# w600 register map
File version: v0.1
Registers are 32-bit, read-write, reset 0x0 unless marked. A register's access mark holds for its fields unless they carry their own. Offsets are from the block's base; [hi:lo] are bit positions; {n}, {i} and the like mark numbered series; <NAME> marks a mode.

## spi
Base 0x40000200
0x00 ch_cfg — 用以对收发通道的相关项进行一些配置
  [30:23] rx_invalid_bit — 表示接收通路在开始接收时，前多少 bit 是无效数据，这些无效数据需要直接扔掉，不进入Rx FIFO。只有后续的数据进入Rx FIFO本寄存器与Tx/Rx length 配合使用。最后实际存入 Rx FIFO 的数据量为Tx/Rx length- RX_INVALID_BIT注：master 模式有效Motorola/ TI 模式有效
  [18:3] tx — /Rx lengthSpi 在传输时，有效的SCK 数也间接的反映了发送或者接收数据的长度。当（TxChOn=1，RxChOn=1）时，表示发送的 bit 数，以及最大接收的bit 数（具体接收多少与RX_INVALID_BIT 有关）当（TxChOn=1，RxChOn=0）时，表示发送的bit 数，当（TxChOn=0，RxChOn=1）时，表示最大接收的 bit 数（具体接收多少与 RX_INVALID_BIT 有关，实际接收数为Tx/Rx length - RX_INVALID_BIT）当（TxChOn=0，RxChOn=0）时，无意义。注：master 有效Motorola/TI/microwire 模式有效
  [0] rsv
  [0] clear — FIFOs，清除 Tx 和Rx FIFO 的内容,同时同步复位master 和slave 所有电路（配置寄存器除外）软件置 1，硬件清 0注：master/slave 都有效Motorola/TI/microwire 模式有效
    0=不清除FIFO; 1=清除有效
  [0] continue — mode，该模式下，spi 发送不受Tx FIFO 空的影响。，持续传输，直至整个传输过程完成。Rx FIFO 满后，SCK 停止翻转，等待RX FIFO 有空间接收数据满，则需要暂停传输，直至rx fifo 可以存数为止注：master 有效一般情况下，不设置该模式。开启该模式时，如果tx fifo 中没有数据，有可能导致无效数据先发送出去。所以请先填入数据后，再启动spi masterMotorola/TI/microwire 模式有效
    0=normal,Tx FIFO 空后，需要等待FIFO 中出现数据，SCK 停止翻转，同理，; 1=continue mode，Tx fifo 空，仍可以传输，直至传输完成，但此时如果rx fifo
  [0] rxchon — 注：master/slave 都有效Motorola/TI/microwire 模式有效
    0=: Rx channel off; 1=: Rx channel on
  [0] txchon — 注：master/slave 都有效Motorola/TI/microwire 模式有效
    0=: Tx channel off; 1=: Tx channel on
  [0] chip — selects注：master 有效Motorola/TI/microwire 模式有效
    0=SPI_CS 有效信号为 0; 1=SPI_CS 有效信号为 1
  [0] force — CS out该信号配合Chip selects 可以实现输出csn 信号可编程，即该信号为 1 时，spi_cs =Chip selects注：master 有效Motorola/TI/microwire 模式有效
    0=spi_cs 信号输出由硬件控制; 1=spi_cs 信号输出由软件控制，具体输出值为Chip selects
  [0] spi — start,命令 SPI 开始接收或者发送，写 1 为spi 开始工作，之后，自动归零Motorola/TI/microwire 模式有效
    0=停止spi 工作; 1=启动spi 的一次发送或者接收，自动归零注master 有效
0x04 spi_cfg reset 0x4 — 对 SPI 通信相关项进行配置
  [31:19] rsv
  [18:17] fram — FORMAT选择master 支持那个厂家的协议注：master 有效
    0=:motorola 2’b01:TI; 2=:microwire 2’b11:RSV
  [14:12] cs — hold， spi_cs 在数据传输完成后持续有效的时间，即spi_cs 的hold 时间注： master 有效Motorola 模式有效
    0=>=1 个APB 总线 CLK; 1=>=2 个APB 总线CLK; 2=>=4 个APB 总线 CLK; 3=>=8 个APB 总线 CLK; 4=>=16 个APB 总线 CLK; 5=>=32 个APB 总线 CLK; 6=>=64 个APB 总线 CLK; 7=>=127 个APB 总线 CLK
  [11:9] cs — setup， spi_cs 在数据传输前提前有效的时间，即spi_cs 的setup 时间Motorola 模式有效注：master 有效
    0=>=1 个APB 总线 CLK; 1=>=2 个APB 总线 CLK; 2=>=4 个APB 总线 CLK; 3=>=8 个APB 总线 CLK; 4=>=16 个APB 总线 CLK; 5=>=32 个APB 总线 CLK; 6=>=64 个APB 总线 CLK; 7=>=127 个APB 总线 CLK
  [8:7] spi — -out delay, SPI 数据输出相对与SCK 的delay，主要是为了hold time 考虑。[8:7] 系统时钟周期数(APB clock)注：master/slave 都有效Motorola 模式有效
    {v}={v} (v=0..3)
  [6:4] frame — delay，默认在一帧（spi_cs 有效期间）传输结束到下一帧开始的间隔为SCK时钟周期的一半，即SPI_CS 无效时间。但为了兼容性，此处可配置。默认至少0.5SCK [6:4] SCK clock例如，按照 block 模式传输 128byte 的数据，数据传输完成后，会加入所设置的延迟时间。注：master 有效
    0=0; 1=2; 2=4; 3=8; 4=16; 5=32; 6=64; 7=127
  [0] spi_tx — pin always drivenMotorola/TI/microwire 模式有效
    0=spi 输出只有在spi_cs 有效时，被驱动，其它时间为三态; 1=spi 输出一直有驱动，即使没有数据传输注master/slave 都有效
  [0] rsv
  [0] bigendian
    0=数据格式采用小端模式，即传输过程中，先发低字节; 1=数据格式采用大端模式，即传输过程中，先发高字节
  [0] master — /SLAVE注：master/slave 都有效
    0=slave，该设备是slave 1’b1master，该设备是master
  [0] spi — CPHA注：master/slave 都有效Motorola 模式有效
    0=传输模式A; 1=传输模式B
  [0] spi — CPOL，SCK 在 IDLE 时的极性注：master/slave 都有效Motorola 模式有效
    0=SCK IDLE 时为 0; 1=SCK IDLE 时为 1
0x08 clk_cfg — 用以设置时钟分频系数
  [31:16] rsv
  [31:16] rsv
  [15:0] divider — FSCK = FAPB_CLK/ ( 2 x (Divider +1))注：master 有效Motorola/TI/microwire 模式有效
  [15:0] divider — FSCK = FAPB_CLK/ ( 2 x (Divider +1))注：master 有效Motorola/TI/microwire 模式有效
0x0C mode_cfg — 配置传输模式
  [31:9] rsv
  [8:6] rxtrigger — levelRX FIFO 存储的数据触发中断或者DMA 请求的阈值：0~7word只有rxbuffer 中的数据大于RxTrigger level，才会触发中断或者请求DMA 搬移注：master/slave 都有效Motorola/TI/microwire 模式有效
  [4:2] txtrigger — levelTX FIFO 存储的数据触发中断或者DMA 请求的阈值：0~7word只有txbuffer 中的数据大于等于TxTrigger level，才会触发中断或者请求 DMA 搬移注：master/slave 都有效Motorola/TI/microwire 模式有效
  [0] rsv
  [0] rxdma — On，采用DMA 搬移数据使能注：master/slave 都有效Motorola/TI/microwire 模式有效
    0=不采用DMA，; 1=采用DMA
  [0] txdma — On，采用DMA 搬移数据使能注：master/slave 都有效Motorola/TI/microwire 模式有效
    0=不采用DMA，; 1=采用DMA
0x10 spi_int_mask reset 0xFF — 屏蔽或者使能相关中断
  [31:8] rsv
  [0] inten_spi_timeout — Motorola/TI/microwire 模式有效
    0=允许产生spi_timeout 中断 1’b1 不允许产生spi_timeout 中断注master/slave 都有效
  [0] inten_spi_done — 注：master/slave 都有效Motorola/TI/microwire 模式有效
    0=spi 发送或者接收完成，允许产生中断; 1=spi 发送或者接收完成，不允许产生中断
  [0] intenrxoverrun — 注：master/slave 都有效Motorola/TI/microwire 模式有效
    0=Rx FIFO overflow 中断使能; 1=Rx FIFO overflow 中断不使能
  [0] intenrxunderrun — 注：master/slave 都有效Motorola/TI/microwire 模式有效
    0=Rx FIFO underflow 中断不使能; 1=Rx FIFO underflow 中断使能
  [0] intentxoverrun — 注：master/slave 都有效Motorola/TI/microwire 模式有效
    0=Tx FIFO overflow 中断使能; 1=Tx FIFO overflow 中断不使能
  [0] intentxunderrun — 注：master/slave 都有效Motorola/TI/microwire 模式有效
    0=Tx FIFO underflow 中断使能; 1=Tx FIFO underflow 中断不使能
  [0] intenrxfifordy — 注：master/slave 都有效Motorola/TI/microwire 模式有效
    0=Rx FIFO 有数据上传中断使能; 1=Rx FIFO 有数据上传中断不使能
  [0] intentxfifordy — 注：master/slave 都有效Motorola/TI/microwire 模式有效
    0=Tx FIFO 可以向TX FIFO 写数据中断使能; 1=Tx FIFO 可以向TX FIFO 写数据中断不使能
0x14 spi_int_source — 用于查询中断源
  [31:8] rsv
  [0] spi_timeout — 注：master/slave 都有效Motorola/TI/microwire 模式有效
    0=rxfifo 中没有结尾数据需要CPU 取走; 1=rxfifo 中有结尾数据需要CPU 取走写 1 清零
  [0] spi_done — 注：master/slave 都有效Motorola/TI/microwire 模式有效
    0=SPI 发送或者接收没有完成; 1=SPI 发送或者接收完成写 1 清零
  [0] rxoverrun — 写 1 清零注：master/slave 都有效Motorola/TI/microwire 模式有效
    0=Rx FIFO overflow 1’b1Rx FIFO overflow
  [0] rxunderrun — 注：master/slave 都有效Motorola/TI/microwire 模式有效
    0=Rx FIFO underflow 1’b1Rx FIFO underflow写 1 清零
  [0] txoverrun — 注：master/slave 都有效Motorola/TI/microwire 模式有效
    0=Tx FIFO overflow 1’b1Tx FIFO overflow写 1 清零
  [0] txunderrun — 在 continue mode = 1 的情况下，永远不会产生该中断。注：master/slave 都有效Motorola/TI/microwire 模式有效
    0=Tx FIFO underflow 1’b1Tx FIFO underflow写 1 清零
  [0] rxfifordy — 写 1 清零注：master/slave 都有效Motorola/TI/microwire 模式有效
    0=Rx FIFO 数据量<= RxTrigger level，不需要上传 1’b1Rx FIFO 数据量> RxTrigger level，要求上传
  [0] txfifordy — 注：master/slave 都有效Motorola/TI/microwire 模式有效
    0=Tx FIFO 数据量 > TxTrigger level，不可以向TX FIFO 写数据 1’b1Tx FIFO 数据量 <= TxTrigger level，可以向TX FIFO 写数据写 1 清零
0x18 spi_status ro — 列举 SPI 通信中的相关状态
  [31:13] rsv
  [11:6] rx — FIFO fill levelRx FIFO 中数据量，单位为字节注：master/slave 都有效Motorola/TI/microwire 模式有效
  [0] spi — Busy注：master/slave 都有效Motorola/TI/microwire 模式有效
    on read: 0=SPI 没有发送和接收任务; 1=SPI 处于发送或者接收过程
  [5:0] tx — FIFO fill levelTx FIFO 中数据量，单位为字节注：master/slave 都有效Motorola/TI/microwire 模式有效
0x1C spi_time_out — 设置 SPI 通信超时
  [0] spi_timer_en — 注：master/slave 都有效Motorola/TI/microwire 模式有效
    0=不允许timer 计时; 1=:允许timer 计时
  [30:0] spi_time_out — 当一次传输完成后，在接收通路 rxfifo 中，结尾的数据如果不能触发接收中断RxFifoRdy 或者DMA 请求时，需要采用计时机制来通知CPU 搬走结尾数据。具体方法：当 rxfifo 处于idle 状态下（没有读写操作，没有 dma 请求，cs 无效，rxfifo中有数据，且数据量小于等于 RxTrigger level），开始计数，达到本寄存器设置的值，则触发timeout 中断，请求CPU 搬走结尾数据。任何对rxfifo 的读写操作都会清楚timeout 计时器。所表示的时间为： T = SPI_TIME_OUT/FAPB_CLK注：master/slave 都有效Motorola/TI/microwire 模式有效
0x20 spi_tx_data — TX FIFO，用于存放待发送数据
  [31:0] spi_tx_data — 向Tx FIFO 写数据的窗口地址注：master/slave 都有效Motorola/TI/microwire 模式有效
0x24 trans_mode — 设置传输模式
  [31:30] rsv
  [29:24] ti_blk_len — 在TI 的时序模式下，每个 block 传输的长度，即每次 CS 有效之后的传输数据长度。支持 4~32bit……..TI 模式有效
    4=: 4bit 长数据 6’h5: 5bit 长数据 6’h6: 6bit 长数据; 32=: 32bit 长数据注master 有效
  [13:8] micro_dat_len — Microwire 模式下，在burst 模式模式时，每个burst 传输数据的长度从 1~32：……..
    1=: 1bit 长数据 6’h2: 2bit 长数据 6’h3: 3bit 长数据; 32=32bit 长数据注master 有效 microwire 模式有效
  [0] micro_burst — 1b’1：Microwire 模式下，采用burst 传输，即 Tx 发送控制字，Rx 接收数据，依次交替进行，MICRO_CONTROL_LEN 表示的是控制字长度，MICRO_DAT_LEN 表示的是发送或者接收字的长度，Tx/Rx length 表示的是整个传输过程中有效 sck， burst 模 式 下 ， 发 送 接 收 交 替 进 行 的 次 数 为 （ Tx/Rx length ）/(MICRO_CONTROL_LEN+ MICRO_DAT_LEN+1)length-MICRO_CONTROL_LEN-1，其中m 表示接收多少个（MICRO_DAT_LEN）长度的字注：master 有效microwire 模式有效1）tx_ch_on = 1, rx_ch_on = 0,此时，只有发送，MICRO_CONTROL_LEN 表示的是控制字长度，Tx/Rx length 表示的是整个传输过程中有效sck，此时发送的数据长度为m*MICRO_DAT_LEN = Tx/Rx length - MICRO_CONTROL_LEN，其中 m 表示发送多少个（MICRO_DAT_LEN）长度的字2 ） tx_ch_on = 1, rx_ch_on = 1 ， 此时， Tx 发送控制字， Rx 接收数据，MICRO_CONTROL_LEN 表示的是控制字长度，Tx/Rx length 表示的是整个传输过程 中 有 效 sck ， 接 收 数 据 长 度 为 m*MICRO_DAT_LEN = Tx/Rx
    0=Microwire 模式下，不采用burst 传输在此模式下，有两种情况
  [5:0] micro_control_len — Microwire 模式下，命令字的长度从 1~32：……..microwire 模式有效
    1=: 1bit 长命令 6’h2: 2bit 长命令 6’h3: 3bit 长命令; 32=32bit 长命令注master 有效
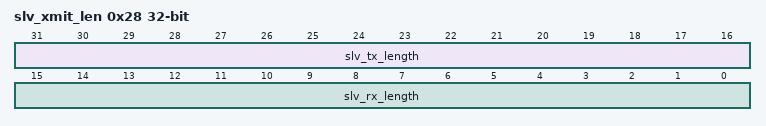
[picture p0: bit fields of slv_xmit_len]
0x28 slv_xmit_len ro — 作为从设备时用于存放发送出去或者接收到的数据的长度
  [31:16] slv_tx_length — 作为slave 时，在 cs 有效期间，发送出去的数据长度，单位为bit注：slave 有效Motorola 模式有效
  [15:0] slv_rx_length — 作为slave 时，在 cs 有效期间，接收到的数据长度，单位为bit注：slave 有效Motorola 模式有效
0x30 spi_rx_data — RX FIFO，用于存放接收到的数据
  [31:0] rx_address ro — 从Rx FIFO 读数据的窗口地址注：master/slave 都有效Motorola/TI/microwire 模式有效
